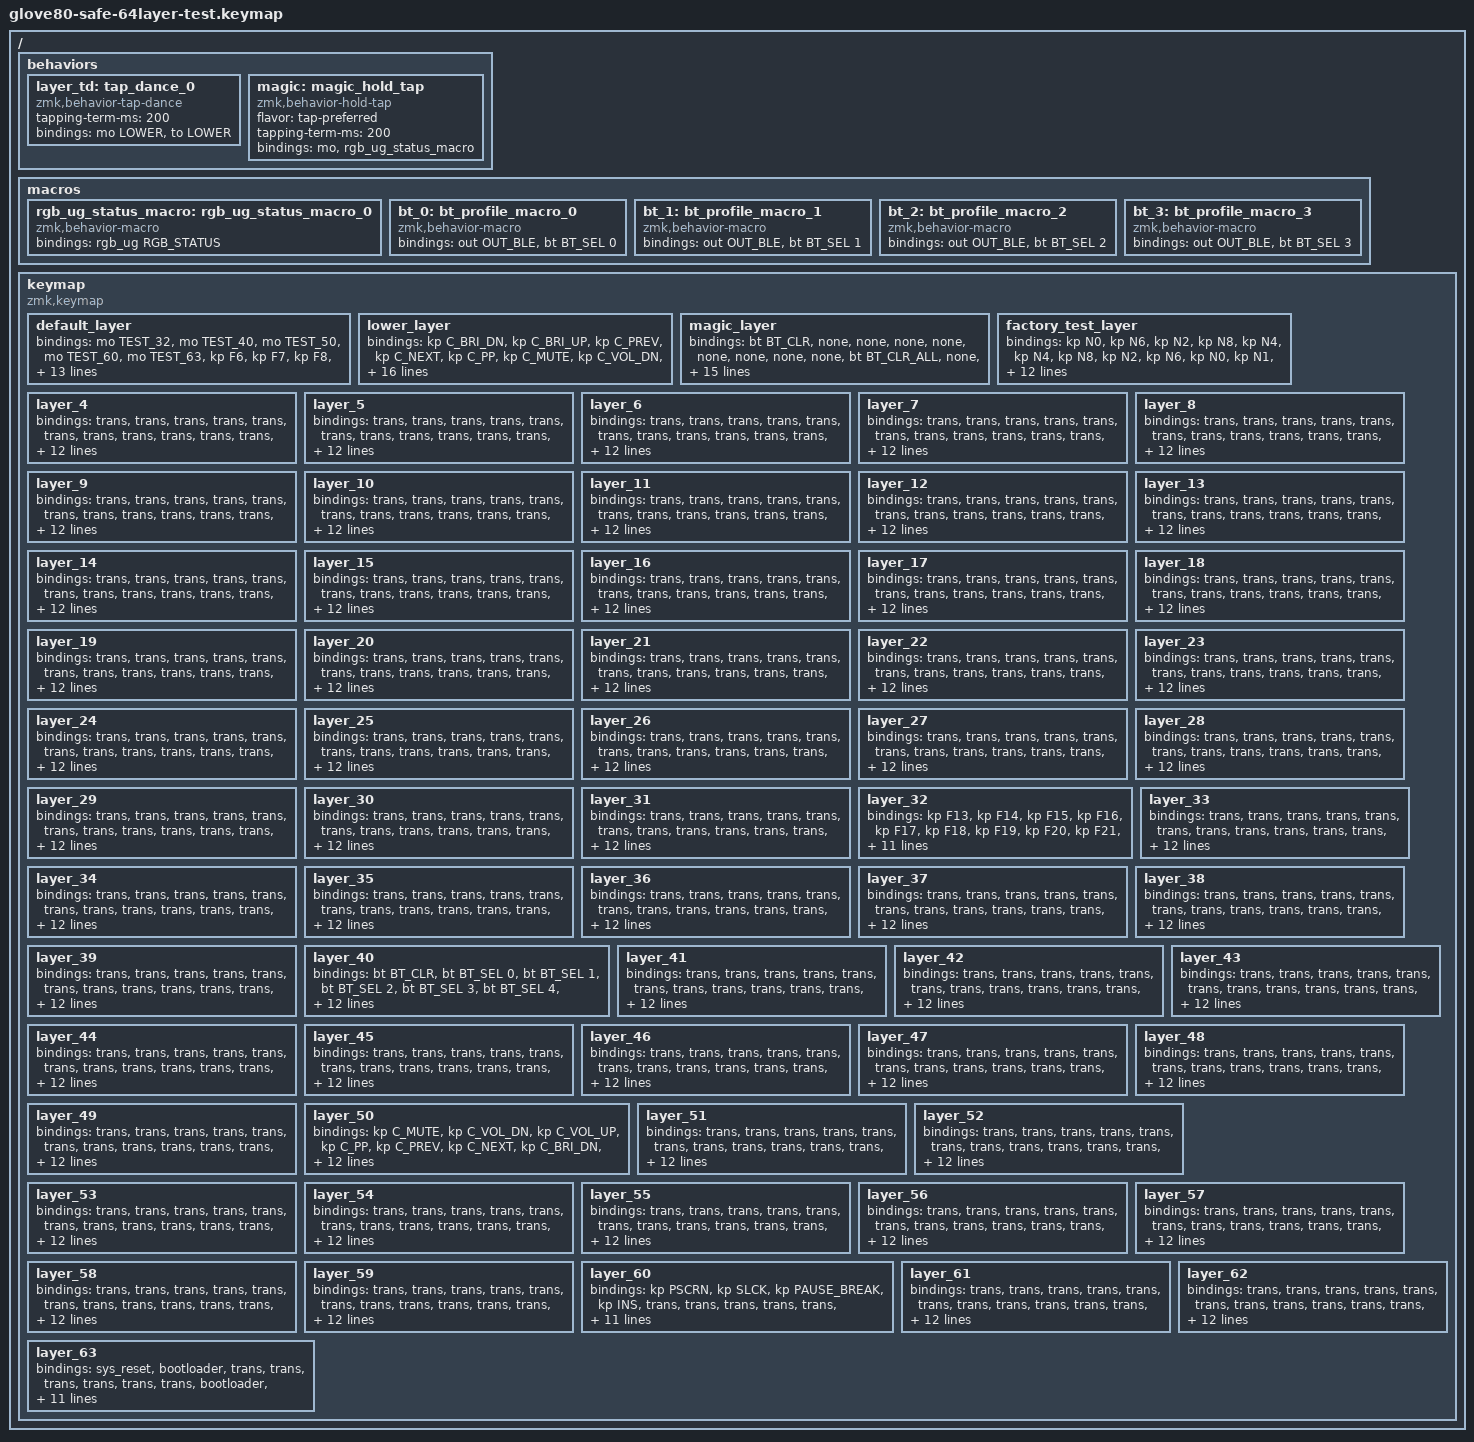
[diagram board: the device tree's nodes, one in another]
/*
 * SAFE 64-Layer Test Keymap for Glove80
 *
 * This keymap PRESERVES all MoErgo factory functionality:
 * - Layer 0 (DEFAULT): Standard Glove80 layout
 * - Layer 1 (LOWER): Function/numpad layer
 * - Layer 2 (MAGIC): Bootloader, reset, RGB, Bluetooth controls
 * - Layer 3 (FACTORY_TEST): Factory testing layer
 *
 * ADDS layers 4-63 to test 64-layer support:
 * - Layers 4-31: Empty placeholder layers (just &trans)
 * - Layers 32-63: Test layers with unique bindings to prove high layers work
 *
 * Test keys added to default layer (F1-F5 row):
 * - F1 = &mo 32 (access layer 32 - proves layers > 31 work!)
 * - F2 = &mo 40 (access layer 40)
 * - F3 = &mo 50 (access layer 50)
 * - F4 = &mo 60 (access layer 60)
 * - F5 = &mo 63 (access layer 63 - highest possible!)
 */

#include <behaviors.dtsi>
#include <dt-bindings/zmk/keys.h>
#include <dt-bindings/zmk/bt.h>
#include <dt-bindings/zmk/ext_power.h>
#include <dt-bindings/zmk/outputs.h>
#include <dt-bindings/zmk/rgb.h>

#define HYPER LC(LS(LG(LALT)))

// Factory layers (DO NOT CHANGE!)
#define DEFAULT 0
#define LOWER 1
#define MAGIC 2
#define FACTORY_TEST 3

// Test layers (layers 32+ ONLY work with 64-bit support!)
#define TEST_32 32
#define TEST_40 40
#define TEST_50 50
#define TEST_60 60
#define TEST_63 63

/ {
    behaviors {
        // Factory behaviors - DO NOT MODIFY
        layer_td: tap_dance_0 {
            compatible = "zmk,behavior-tap-dance";
            #binding-cells = <0>;
            tapping-term-ms = <200>;
            bindings = <&mo LOWER>, <&to LOWER>;
        };

        magic: magic_hold_tap {
            compatible = "zmk,behavior-hold-tap";
            #binding-cells = <2>;
            flavor = "tap-preferred";
            tapping-term-ms = <200>;
            bindings = <&mo>, <&rgb_ug_status_macro>;
        };
    };

    macros {
        // Factory macros - DO NOT MODIFY
        rgb_ug_status_macro: rgb_ug_status_macro_0 {
            compatible = "zmk,behavior-macro";
            #binding-cells = <0>;
            bindings = <&rgb_ug RGB_STATUS>;
        };

        bt_0: bt_profile_macro_0 {
            compatible = "zmk,behavior-macro";
            #binding-cells = <0>;
            bindings = <&out OUT_BLE>, <&bt BT_SEL 0>;
        };

        bt_1: bt_profile_macro_1 {
            compatible = "zmk,behavior-macro";
            #binding-cells = <0>;
            bindings = <&out OUT_BLE>, <&bt BT_SEL 1>;
        };

        bt_2: bt_profile_macro_2 {
            compatible = "zmk,behavior-macro";
            #binding-cells = <0>;
            bindings = <&out OUT_BLE>, <&bt BT_SEL 2>;
        };

        bt_3: bt_profile_macro_3 {
            compatible = "zmk,behavior-macro";
            #binding-cells = <0>;
            bindings = <&out OUT_BLE>, <&bt BT_SEL 3>;
        };
    };

    keymap {
        compatible = "zmk,keymap";

        // ====================================================================
        // LAYER 0: DEFAULT (Factory layout with test layer access on F-keys)
        // ====================================================================
        default_layer {
            // MODIFIED: F1-F5 now access test layers to prove 64-layer support works
            // Hold F1 = Layer 32, F2 = Layer 40, F3 = Layer 50, F4 = Layer 60, F5 = Layer 63
            // Release = return to base layer (momentary activation)

            bindings = <
            &mo TEST_32    &mo TEST_40 &mo TEST_50 &mo TEST_60 &mo TEST_63                                                                                        &kp F6  &kp F7      &kp F8      &kp F9      &kp F10
            &kp EQUAL      &kp N1      &kp N2      &kp N3      &kp N4      &kp N5                                                                     &kp N6  &kp N7  &kp N8      &kp N9      &kp N0      &kp MINUS
            &kp TAB        &kp Q       &kp W       &kp E       &kp R       &kp T                                                                      &kp Y   &kp U   &kp I       &kp O       &kp P       &kp BSLH
            &kp ESC        &kp A       &kp S       &kp D       &kp F       &kp G                                                                      &kp H   &kp J   &kp K       &kp L       &kp SEMI    &kp SQT
            &kp GRAVE      &kp Z       &kp X       &kp C       &kp V       &kp B   &kp LSHFT   &kp LCTRL   &layer_td  &kp LGUI  &kp RCTRL &kp RSHFT   &kp N   &kp M   &kp COMMA   &kp DOT     &kp FSLH    &kp PG_UP
            &magic MAGIC 0 &kp HOME    &kp END     &kp LEFT    &kp RIGHT           &kp BSPC    &kp DEL     &kp LALT   &kp RALT  &kp RET   &kp SPACE           &kp UP  &kp DOWN    &kp LBKT    &kp RBKT    &kp PG_DN
            >;
        };

        // ====================================================================
        // LAYER 1: LOWER (Factory - DO NOT MODIFY)
        // ====================================================================
        lower_layer {
            bindings = <
            &kp C_BRI_DN      &kp C_BRI_UP        &kp C_PREV      &kp C_NEXT      &kp C_PP                                                                                                           &kp C_MUTE   &kp C_VOL_DN &kp C_VOL_UP  &none           &kp PAUSE_BREAK
            &trans            &none               &none           &none           &none           &kp HOME                                                                              &kp LPAR     &kp KP_NUM   &kp KP_EQUAL &kp KP_DIVIDE &kp KP_MULTIPLY &kp PSCRN
            &trans            &none               &none           &kp UP          &none           &kp END                                                                               &kp RPAR     &kp KP_N7    &kp KP_N8    &kp KP_N9     &kp KP_MINUS    &kp SLCK
            &trans            &none               &kp LEFT        &kp DOWN        &kp RIGHT       &kp PG_UP                                                                             &kp PRCNT    &kp KP_N4    &kp KP_N5    &kp KP_N6     &kp KP_PLUS     &none
            &trans            &kp K_CMENU         &none           &kp F11         &kp F12         &kp PG_DN       &trans      &trans      &to DEFAULT &trans      &trans      &trans    &kp COMMA    &kp KP_N1    &kp KP_N2    &kp KP_N3     &kp KP_ENTER    &trans
            &trans            &kp CAPS            &kp INS         &kp F11         &kp F12                         &trans      &trans      &trans      &trans      &trans      &trans                 &kp KP_N0    &kp KP_N0    &kp KP_DOT    &kp KP_ENTER    &trans
            >;
        };

        // ====================================================================
        // LAYER 2: MAGIC (Factory - DO NOT MODIFY - CRITICAL FOR BOOTLOADER!)
        // ====================================================================
        magic_layer {
            bindings = <
            &bt BT_CLR        &none               &none           &none           &none                                                                                                           &none      &none      &none      &none      &bt BT_CLR_ALL
            &none             &none               &none           &none           &none           &none                                                                                &none      &none      &none      &none      &none      &none
            &none             &rgb_ug RGB_SPI     &rgb_ug RGB_SAI &rgb_ug RGB_HUI &rgb_ug RGB_BRI &rgb_ug RGB_TOG                                                                      &none      &none      &none      &none      &none      &none
            &bootloader       &rgb_ug RGB_SPD     &rgb_ug RGB_SAD &rgb_ug RGB_HUD &rgb_ug RGB_BRD &rgb_ug RGB_EFF                                                                      &none      &none      &none      &none      &none      &bootloader
            &sys_reset        &none               &none           &none           &none           &none           &bt_2     &bt_3     &none            &none     &none     &none       &none      &none      &none      &none      &none      &sys_reset
            &none             &none               &none           &none           &none                           &bt_0     &bt_1     &out OUT_USB     &none     &none     &none                  &none      &none      &none      &none      &to FACTORY_TEST
            >;
        };

        // ====================================================================
        // LAYER 3: FACTORY_TEST (Factory - DO NOT MODIFY)
        // ====================================================================
        factory_test_layer {
            bindings = <
            &kp N0   &kp N6   &kp N2   &kp N8   &kp N4                                                                              &kp N4   &kp N8   &kp N2   &kp N6   &kp N0
            &kp N1   &kp N7   &kp N3   &kp N9   &kp N5   &kp N0                                                            &kp N0   &kp N5   &kp N9   &kp N3   &kp N7   &kp N1
            &kp N2   &kp N8   &kp N4   &kp N0   &kp N6   &kp N1                                                            &kp N1   &kp N6   &kp N0   &kp N4   &kp N8   &kp N2
            &kp N3   &kp N9   &kp N5   &kp N1   &kp N7   &kp N2                                                            &kp N2   &kp N7   &kp N1   &kp N5   &kp N9   &kp N3
            &kp N4   &kp N0   &kp N6   &kp N2   &kp N8   &kp N3   &kp N4   &kp N5   &kp N6      &kp N6   &kp N5   &kp N4   &kp N3   &kp N8   &kp N2   &kp N6   &kp N0   &kp N4
            &kp N5   &kp N1   &kp N7   &kp N3   &kp N9            &kp N7   &kp N8   &kp N9      &kp N9   &kp N8   &kp N7            &kp N9   &kp N3   &kp N7   &kp N1   &kp N5
            >;
        };

        // ====================================================================
        // LAYERS 4-31: Placeholder layers (standard 32-bit support range)
        // ====================================================================
        // These layers just pass through to lower layers with &trans
        // They exist to fill the gap between factory layers and test layers

        layer_4  { bindings = <&trans &trans &trans &trans &trans &trans &trans &trans &trans &trans &trans &trans &trans &trans &trans &trans &trans &trans &trans &trans &trans &trans &trans &trans &trans &trans &trans &trans &trans &trans &trans &trans &trans &trans &trans &trans &trans &trans &trans &trans &trans &trans &trans &trans &trans &trans &trans &trans &trans &trans &trans &trans &trans &trans &trans &trans &trans &trans &trans &trans &trans &trans &trans &trans &trans &trans &trans &trans &trans &trans &trans &trans &trans &trans &trans &trans &trans &trans &trans &trans>; };
        layer_5  { bindings = <&trans &trans &trans &trans &trans &trans &trans &trans &trans &trans &trans &trans &trans &trans &trans &trans &trans &trans &trans &trans &trans &trans &trans &trans &trans &trans &trans &trans &trans &trans &trans &trans &trans &trans &trans &trans &trans &trans &trans &trans &trans &trans &trans &trans &trans &trans &trans &trans &trans &trans &trans &trans &trans &trans &trans &trans &trans &trans &trans &trans &trans &trans &trans &trans &trans &trans &trans &trans &trans &trans &trans &trans &trans &trans &trans &trans &trans &trans &trans &trans>; };
        layer_6  { bindings = <&trans &trans &trans &trans &trans &trans &trans &trans &trans &trans &trans &trans &trans &trans &trans &trans &trans &trans &trans &trans &trans &trans &trans &trans &trans &trans &trans &trans &trans &trans &trans &trans &trans &trans &trans &trans &trans &trans &trans &trans &trans &trans &trans &trans &trans &trans &trans &trans &trans &trans &trans &trans &trans &trans &trans &trans &trans &trans &trans &trans &trans &trans &trans &trans &trans &trans &trans &trans &trans &trans &trans &trans &trans &trans &trans &trans &trans &trans &trans &trans>; };
        layer_7  { bindings = <&trans &trans &trans &trans &trans &trans &trans &trans &trans &trans &trans &trans &trans &trans &trans &trans &trans &trans &trans &trans &trans &trans &trans &trans &trans &trans &trans &trans &trans &trans &trans &trans &trans &trans &trans &trans &trans &trans &trans &trans &trans &trans &trans &trans &trans &trans &trans &trans &trans &trans &trans &trans &trans &trans &trans &trans &trans &trans &trans &trans &trans &trans &trans &trans &trans &trans &trans &trans &trans &trans &trans &trans &trans &trans &trans &trans &trans &trans &trans &trans>; };
        layer_8  { bindings = <&trans &trans &trans &trans &trans &trans &trans &trans &trans &trans &trans &trans &trans &trans &trans &trans &trans &trans &trans &trans &trans &trans &trans &trans &trans &trans &trans &trans &trans &trans &trans &trans &trans &trans &trans &trans &trans &trans &trans &trans &trans &trans &trans &trans &trans &trans &trans &trans &trans &trans &trans &trans &trans &trans &trans &trans &trans &trans &trans &trans &trans &trans &trans &trans &trans &trans &trans &trans &trans &trans &trans &trans &trans &trans &trans &trans &trans &trans &trans &trans>; };
        layer_9  { bindings = <&trans &trans &trans &trans &trans &trans &trans &trans &trans &trans &trans &trans &trans &trans &trans &trans &trans &trans &trans &trans &trans &trans &trans &trans &trans &trans &trans &trans &trans &trans &trans &trans &trans &trans &trans &trans &trans &trans &trans &trans &trans &trans &trans &trans &trans &trans &trans &trans &trans &trans &trans &trans &trans &trans &trans &trans &trans &trans &trans &trans &trans &trans &trans &trans &trans &trans &trans &trans &trans &trans &trans &trans &trans &trans &trans &trans &trans &trans &trans &trans>; };
        layer_10 { bindings = <&trans &trans &trans &trans &trans &trans &trans &trans &trans &trans &trans &trans &trans &trans &trans &trans &trans &trans &trans &trans &trans &trans &trans &trans &trans &trans &trans &trans &trans &trans &trans &trans &trans &trans &trans &trans &trans &trans &trans &trans &trans &trans &trans &trans &trans &trans &trans &trans &trans &trans &trans &trans &trans &trans &trans &trans &trans &trans &trans &trans &trans &trans &trans &trans &trans &trans &trans &trans &trans &trans &trans &trans &trans &trans &trans &trans &trans &trans &trans &trans>; };
        layer_11 { bindings = <&trans &trans &trans &trans &trans &trans &trans &trans &trans &trans &trans &trans &trans &trans &trans &trans &trans &trans &trans &trans &trans &trans &trans &trans &trans &trans &trans &trans &trans &trans &trans &trans &trans &trans &trans &trans &trans &trans &trans &trans &trans &trans &trans &trans &trans &trans &trans &trans &trans &trans &trans &trans &trans &trans &trans &trans &trans &trans &trans &trans &trans &trans &trans &trans &trans &trans &trans &trans &trans &trans &trans &trans &trans &trans &trans &trans &trans &trans &trans &trans>; };
        layer_12 { bindings = <&trans &trans &trans &trans &trans &trans &trans &trans &trans &trans &trans &trans &trans &trans &trans &trans &trans &trans &trans &trans &trans &trans &trans &trans &trans &trans &trans &trans &trans &trans &trans &trans &trans &trans &trans &trans &trans &trans &trans &trans &trans &trans &trans &trans &trans &trans &trans &trans &trans &trans &trans &trans &trans &trans &trans &trans &trans &trans &trans &trans &trans &trans &trans &trans &trans &trans &trans &trans &trans &trans &trans &trans &trans &trans &trans &trans &trans &trans &trans &trans>; };
        layer_13 { bindings = <&trans &trans &trans &trans &trans &trans &trans &trans &trans &trans &trans &trans &trans &trans &trans &trans &trans &trans &trans &trans &trans &trans &trans &trans &trans &trans &trans &trans &trans &trans &trans &trans &trans &trans &trans &trans &trans &trans &trans &trans &trans &trans &trans &trans &trans &trans &trans &trans &trans &trans &trans &trans &trans &trans &trans &trans &trans &trans &trans &trans &trans &trans &trans &trans &trans &trans &trans &trans &trans &trans &trans &trans &trans &trans &trans &trans &trans &trans &trans &trans>; };
        layer_14 { bindings = <&trans &trans &trans &trans &trans &trans &trans &trans &trans &trans &trans &trans &trans &trans &trans &trans &trans &trans &trans &trans &trans &trans &trans &trans &trans &trans &trans &trans &trans &trans &trans &trans &trans &trans &trans &trans &trans &trans &trans &trans &trans &trans &trans &trans &trans &trans &trans &trans &trans &trans &trans &trans &trans &trans &trans &trans &trans &trans &trans &trans &trans &trans &trans &trans &trans &trans &trans &trans &trans &trans &trans &trans &trans &trans &trans &trans &trans &trans &trans &trans>; };
        layer_15 { bindings = <&trans &trans &trans &trans &trans &trans &trans &trans &trans &trans &trans &trans &trans &trans &trans &trans &trans &trans &trans &trans &trans &trans &trans &trans &trans &trans &trans &trans &trans &trans &trans &trans &trans &trans &trans &trans &trans &trans &trans &trans &trans &trans &trans &trans &trans &trans &trans &trans &trans &trans &trans &trans &trans &trans &trans &trans &trans &trans &trans &trans &trans &trans &trans &trans &trans &trans &trans &trans &trans &trans &trans &trans &trans &trans &trans &trans &trans &trans &trans &trans>; };
        layer_16 { bindings = <&trans &trans &trans &trans &trans &trans &trans &trans &trans &trans &trans &trans &trans &trans &trans &trans &trans &trans &trans &trans &trans &trans &trans &trans &trans &trans &trans &trans &trans &trans &trans &trans &trans &trans &trans &trans &trans &trans &trans &trans &trans &trans &trans &trans &trans &trans &trans &trans &trans &trans &trans &trans &trans &trans &trans &trans &trans &trans &trans &trans &trans &trans &trans &trans &trans &trans &trans &trans &trans &trans &trans &trans &trans &trans &trans &trans &trans &trans &trans &trans>; };
        layer_17 { bindings = <&trans &trans &trans &trans &trans &trans &trans &trans &trans &trans &trans &trans &trans &trans &trans &trans &trans &trans &trans &trans &trans &trans &trans &trans &trans &trans &trans &trans &trans &trans &trans &trans &trans &trans &trans &trans &trans &trans &trans &trans &trans &trans &trans &trans &trans &trans &trans &trans &trans &trans &trans &trans &trans &trans &trans &trans &trans &trans &trans &trans &trans &trans &trans &trans &trans &trans &trans &trans &trans &trans &trans &trans &trans &trans &trans &trans &trans &trans &trans &trans>; };
        layer_18 { bindings = <&trans &trans &trans &trans &trans &trans &trans &trans &trans &trans &trans &trans &trans &trans &trans &trans &trans &trans &trans &trans &trans &trans &trans &trans &trans &trans &trans &trans &trans &trans &trans &trans &trans &trans &trans &trans &trans &trans &trans &trans &trans &trans &trans &trans &trans &trans &trans &trans &trans &trans &trans &trans &trans &trans &trans &trans &trans &trans &trans &trans &trans &trans &trans &trans &trans &trans &trans &trans &trans &trans &trans &trans &trans &trans &trans &trans &trans &trans &trans &trans>; };
        layer_19 { bindings = <&trans &trans &trans &trans &trans &trans &trans &trans &trans &trans &trans &trans &trans &trans &trans &trans &trans &trans &trans &trans &trans &trans &trans &trans &trans &trans &trans &trans &trans &trans &trans &trans &trans &trans &trans &trans &trans &trans &trans &trans &trans &trans &trans &trans &trans &trans &trans &trans &trans &trans &trans &trans &trans &trans &trans &trans &trans &trans &trans &trans &trans &trans &trans &trans &trans &trans &trans &trans &trans &trans &trans &trans &trans &trans &trans &trans &trans &trans &trans &trans>; };
        layer_20 { bindings = <&trans &trans &trans &trans &trans &trans &trans &trans &trans &trans &trans &trans &trans &trans &trans &trans &trans &trans &trans &trans &trans &trans &trans &trans &trans &trans &trans &trans &trans &trans &trans &trans &trans &trans &trans &trans &trans &trans &trans &trans &trans &trans &trans &trans &trans &trans &trans &trans &trans &trans &trans &trans &trans &trans &trans &trans &trans &trans &trans &trans &trans &trans &trans &trans &trans &trans &trans &trans &trans &trans &trans &trans &trans &trans &trans &trans &trans &trans &trans &trans>; };
        layer_21 { bindings = <&trans &trans &trans &trans &trans &trans &trans &trans &trans &trans &trans &trans &trans &trans &trans &trans &trans &trans &trans &trans &trans &trans &trans &trans &trans &trans &trans &trans &trans &trans &trans &trans &trans &trans &trans &trans &trans &trans &trans &trans &trans &trans &trans &trans &trans &trans &trans &trans &trans &trans &trans &trans &trans &trans &trans &trans &trans &trans &trans &trans &trans &trans &trans &trans &trans &trans &trans &trans &trans &trans &trans &trans &trans &trans &trans &trans &trans &trans &trans &trans>; };
        layer_22 { bindings = <&trans &trans &trans &trans &trans &trans &trans &trans &trans &trans &trans &trans &trans &trans &trans &trans &trans &trans &trans &trans &trans &trans &trans &trans &trans &trans &trans &trans &trans &trans &trans &trans &trans &trans &trans &trans &trans &trans &trans &trans &trans &trans &trans &trans &trans &trans &trans &trans &trans &trans &trans &trans &trans &trans &trans &trans &trans &trans &trans &trans &trans &trans &trans &trans &trans &trans &trans &trans &trans &trans &trans &trans &trans &trans &trans &trans &trans &trans &trans &trans>; };
        layer_23 { bindings = <&trans &trans &trans &trans &trans &trans &trans &trans &trans &trans &trans &trans &trans &trans &trans &trans &trans &trans &trans &trans &trans &trans &trans &trans &trans &trans &trans &trans &trans &trans &trans &trans &trans &trans &trans &trans &trans &trans &trans &trans &trans &trans &trans &trans &trans &trans &trans &trans &trans &trans &trans &trans &trans &trans &trans &trans &trans &trans &trans &trans &trans &trans &trans &trans &trans &trans &trans &trans &trans &trans &trans &trans &trans &trans &trans &trans &trans &trans &trans &trans>; };
        layer_24 { bindings = <&trans &trans &trans &trans &trans &trans &trans &trans &trans &trans &trans &trans &trans &trans &trans &trans &trans &trans &trans &trans &trans &trans &trans &trans &trans &trans &trans &trans &trans &trans &trans &trans &trans &trans &trans &trans &trans &trans &trans &trans &trans &trans &trans &trans &trans &trans &trans &trans &trans &trans &trans &trans &trans &trans &trans &trans &trans &trans &trans &trans &trans &trans &trans &trans &trans &trans &trans &trans &trans &trans &trans &trans &trans &trans &trans &trans &trans &trans &trans &trans>; };
        layer_25 { bindings = <&trans &trans &trans &trans &trans &trans &trans &trans &trans &trans &trans &trans &trans &trans &trans &trans &trans &trans &trans &trans &trans &trans &trans &trans &trans &trans &trans &trans &trans &trans &trans &trans &trans &trans &trans &trans &trans &trans &trans &trans &trans &trans &trans &trans &trans &trans &trans &trans &trans &trans &trans &trans &trans &trans &trans &trans &trans &trans &trans &trans &trans &trans &trans &trans &trans &trans &trans &trans &trans &trans &trans &trans &trans &trans &trans &trans &trans &trans &trans &trans>; };
        layer_26 { bindings = <&trans &trans &trans &trans &trans &trans &trans &trans &trans &trans &trans &trans &trans &trans &trans &trans &trans &trans &trans &trans &trans &trans &trans &trans &trans &trans &trans &trans &trans &trans &trans &trans &trans &trans &trans &trans &trans &trans &trans &trans &trans &trans &trans &trans &trans &trans &trans &trans &trans &trans &trans &trans &trans &trans &trans &trans &trans &trans &trans &trans &trans &trans &trans &trans &trans &trans &trans &trans &trans &trans &trans &trans &trans &trans &trans &trans &trans &trans &trans &trans>; };
        layer_27 { bindings = <&trans &trans &trans &trans &trans &trans &trans &trans &trans &trans &trans &trans &trans &trans &trans &trans &trans &trans &trans &trans &trans &trans &trans &trans &trans &trans &trans &trans &trans &trans &trans &trans &trans &trans &trans &trans &trans &trans &trans &trans &trans &trans &trans &trans &trans &trans &trans &trans &trans &trans &trans &trans &trans &trans &trans &trans &trans &trans &trans &trans &trans &trans &trans &trans &trans &trans &trans &trans &trans &trans &trans &trans &trans &trans &trans &trans &trans &trans &trans &trans>; };
        layer_28 { bindings = <&trans &trans &trans &trans &trans &trans &trans &trans &trans &trans &trans &trans &trans &trans &trans &trans &trans &trans &trans &trans &trans &trans &trans &trans &trans &trans &trans &trans &trans &trans &trans &trans &trans &trans &trans &trans &trans &trans &trans &trans &trans &trans &trans &trans &trans &trans &trans &trans &trans &trans &trans &trans &trans &trans &trans &trans &trans &trans &trans &trans &trans &trans &trans &trans &trans &trans &trans &trans &trans &trans &trans &trans &trans &trans &trans &trans &trans &trans &trans &trans>; };
        layer_29 { bindings = <&trans &trans &trans &trans &trans &trans &trans &trans &trans &trans &trans &trans &trans &trans &trans &trans &trans &trans &trans &trans &trans &trans &trans &trans &trans &trans &trans &trans &trans &trans &trans &trans &trans &trans &trans &trans &trans &trans &trans &trans &trans &trans &trans &trans &trans &trans &trans &trans &trans &trans &trans &trans &trans &trans &trans &trans &trans &trans &trans &trans &trans &trans &trans &trans &trans &trans &trans &trans &trans &trans &trans &trans &trans &trans &trans &trans &trans &trans &trans &trans>; };
        layer_30 { bindings = <&trans &trans &trans &trans &trans &trans &trans &trans &trans &trans &trans &trans &trans &trans &trans &trans &trans &trans &trans &trans &trans &trans &trans &trans &trans &trans &trans &trans &trans &trans &trans &trans &trans &trans &trans &trans &trans &trans &trans &trans &trans &trans &trans &trans &trans &trans &trans &trans &trans &trans &trans &trans &trans &trans &trans &trans &trans &trans &trans &trans &trans &trans &trans &trans &trans &trans &trans &trans &trans &trans &trans &trans &trans &trans &trans &trans &trans &trans &trans &trans>; };
        layer_31 { bindings = <&trans &trans &trans &trans &trans &trans &trans &trans &trans &trans &trans &trans &trans &trans &trans &trans &trans &trans &trans &trans &trans &trans &trans &trans &trans &trans &trans &trans &trans &trans &trans &trans &trans &trans &trans &trans &trans &trans &trans &trans &trans &trans &trans &trans &trans &trans &trans &trans &trans &trans &trans &trans &trans &trans &trans &trans &trans &trans &trans &trans &trans &trans &trans &trans &trans &trans &trans &trans &trans &trans &trans &trans &trans &trans &trans &trans &trans &trans &trans &trans>; };

        // ====================================================================
        // *** LAYERS 32-63: HIGH LAYERS - ONLY WORK WITH 64-BIT SUPPORT! ***
        // ====================================================================
        // If these layers work, it PROVES the 64-layer patch is functioning!

        // LAYER 32: Test layer with X, Y, Z letters (accessed by holding F1 key)
        // Type to see X's, Y's, Z's - proves layer 32 is active!
        layer_32 {
            bindings = <
            &kp F13  &kp F14  &kp F15  &kp F16  &kp F17                                                                                                 &kp F18  &kp F19  &kp F20  &kp F21  &kp F22
            &kp F23  &kp F24  &kp X    &kp X    &kp X    &kp X                                                                               &kp Y    &kp Y    &kp Y    &kp Y    &kp Y    &kp Y
            &trans   &kp X    &kp X    &kp X    &kp X    &kp X                                                                               &kp Y    &kp Y    &kp Y    &kp Y    &kp Y    &trans
            &trans   &kp Z    &kp Z    &kp Z    &kp Z    &kp Z                                                                               &kp Y    &kp Y    &kp Y    &kp Y    &kp Y    &trans
            &trans   &kp Z    &kp Z    &kp Z    &kp Z    &kp Z    &trans   &trans   &trans      &trans   &trans   &trans                    &kp Y    &kp Y    &kp Y    &kp Y    &kp Y    &trans
            &trans   &trans   &trans   &trans   &trans            &trans   &trans   &trans      &trans   &trans   &trans                             &trans   &trans   &trans   &trans   &trans
            >;
        };

        // Layers 33-39: Placeholder
        layer_33 { bindings = <&trans &trans &trans &trans &trans &trans &trans &trans &trans &trans &trans &trans &trans &trans &trans &trans &trans &trans &trans &trans &trans &trans &trans &trans &trans &trans &trans &trans &trans &trans &trans &trans &trans &trans &trans &trans &trans &trans &trans &trans &trans &trans &trans &trans &trans &trans &trans &trans &trans &trans &trans &trans &trans &trans &trans &trans &trans &trans &trans &trans &trans &trans &trans &trans &trans &trans &trans &trans &trans &trans &trans &trans &trans &trans &trans &trans &trans &trans &trans &trans>; };
        layer_34 { bindings = <&trans &trans &trans &trans &trans &trans &trans &trans &trans &trans &trans &trans &trans &trans &trans &trans &trans &trans &trans &trans &trans &trans &trans &trans &trans &trans &trans &trans &trans &trans &trans &trans &trans &trans &trans &trans &trans &trans &trans &trans &trans &trans &trans &trans &trans &trans &trans &trans &trans &trans &trans &trans &trans &trans &trans &trans &trans &trans &trans &trans &trans &trans &trans &trans &trans &trans &trans &trans &trans &trans &trans &trans &trans &trans &trans &trans &trans &trans &trans &trans>; };
        layer_35 { bindings = <&trans &trans &trans &trans &trans &trans &trans &trans &trans &trans &trans &trans &trans &trans &trans &trans &trans &trans &trans &trans &trans &trans &trans &trans &trans &trans &trans &trans &trans &trans &trans &trans &trans &trans &trans &trans &trans &trans &trans &trans &trans &trans &trans &trans &trans &trans &trans &trans &trans &trans &trans &trans &trans &trans &trans &trans &trans &trans &trans &trans &trans &trans &trans &trans &trans &trans &trans &trans &trans &trans &trans &trans &trans &trans &trans &trans &trans &trans &trans &trans>; };
        layer_36 { bindings = <&trans &trans &trans &trans &trans &trans &trans &trans &trans &trans &trans &trans &trans &trans &trans &trans &trans &trans &trans &trans &trans &trans &trans &trans &trans &trans &trans &trans &trans &trans &trans &trans &trans &trans &trans &trans &trans &trans &trans &trans &trans &trans &trans &trans &trans &trans &trans &trans &trans &trans &trans &trans &trans &trans &trans &trans &trans &trans &trans &trans &trans &trans &trans &trans &trans &trans &trans &trans &trans &trans &trans &trans &trans &trans &trans &trans &trans &trans &trans &trans>; };
        layer_37 { bindings = <&trans &trans &trans &trans &trans &trans &trans &trans &trans &trans &trans &trans &trans &trans &trans &trans &trans &trans &trans &trans &trans &trans &trans &trans &trans &trans &trans &trans &trans &trans &trans &trans &trans &trans &trans &trans &trans &trans &trans &trans &trans &trans &trans &trans &trans &trans &trans &trans &trans &trans &trans &trans &trans &trans &trans &trans &trans &trans &trans &trans &trans &trans &trans &trans &trans &trans &trans &trans &trans &trans &trans &trans &trans &trans &trans &trans &trans &trans &trans &trans>; };
        layer_38 { bindings = <&trans &trans &trans &trans &trans &trans &trans &trans &trans &trans &trans &trans &trans &trans &trans &trans &trans &trans &trans &trans &trans &trans &trans &trans &trans &trans &trans &trans &trans &trans &trans &trans &trans &trans &trans &trans &trans &trans &trans &trans &trans &trans &trans &trans &trans &trans &trans &trans &trans &trans &trans &trans &trans &trans &trans &trans &trans &trans &trans &trans &trans &trans &trans &trans &trans &trans &trans &trans &trans &trans &trans &trans &trans &trans &trans &trans &trans &trans &trans &trans>; };
        layer_39 { bindings = <&trans &trans &trans &trans &trans &trans &trans &trans &trans &trans &trans &trans &trans &trans &trans &trans &trans &trans &trans &trans &trans &trans &trans &trans &trans &trans &trans &trans &trans &trans &trans &trans &trans &trans &trans &trans &trans &trans &trans &trans &trans &trans &trans &trans &trans &trans &trans &trans &trans &trans &trans &trans &trans &trans &trans &trans &trans &trans &trans &trans &trans &trans &trans &trans &trans &trans &trans &trans &trans &trans &trans &trans &trans &trans &trans &trans &trans &trans &trans &trans>; };

        // LAYER 40: Test layer with A, B, C letters + Bluetooth (accessed by holding F2 key)
        // Type to see A's, B's, C's - proves layer 40 is active!
        layer_40 {
            bindings = <
            &bt BT_CLR  &bt BT_SEL 0  &bt BT_SEL 1  &bt BT_SEL 2  &bt BT_SEL 3                                                                     &bt BT_SEL 4  &out OUT_BLE  &out OUT_USB  &trans  &trans
            &trans      &kp A         &kp A         &kp A         &kp A         &kp A                                                     &kp B    &kp B         &kp B         &kp B         &kp B   &trans
            &trans      &kp A         &kp A         &kp A         &kp A         &kp A                                                     &kp B    &kp B         &kp B         &kp B         &kp B   &trans
            &trans      &kp C         &kp C         &kp C         &kp C         &kp C                                                     &kp B    &kp B         &kp B         &kp B         &kp B   &trans
            &trans      &kp C         &kp C         &kp C         &kp C         &kp C   &trans  &trans  &trans    &trans  &trans  &trans  &kp B    &kp B         &kp B         &kp B         &kp B   &trans
            &trans      &trans        &trans        &trans        &trans                &trans  &trans  &trans    &trans  &trans  &trans           &trans        &trans        &trans        &trans  &trans
            >;
        };

        // Layers 41-49: Placeholder
        layer_41 { bindings = <&trans &trans &trans &trans &trans &trans &trans &trans &trans &trans &trans &trans &trans &trans &trans &trans &trans &trans &trans &trans &trans &trans &trans &trans &trans &trans &trans &trans &trans &trans &trans &trans &trans &trans &trans &trans &trans &trans &trans &trans &trans &trans &trans &trans &trans &trans &trans &trans &trans &trans &trans &trans &trans &trans &trans &trans &trans &trans &trans &trans &trans &trans &trans &trans &trans &trans &trans &trans &trans &trans &trans &trans &trans &trans &trans &trans &trans &trans &trans &trans>; };
        layer_42 { bindings = <&trans &trans &trans &trans &trans &trans &trans &trans &trans &trans &trans &trans &trans &trans &trans &trans &trans &trans &trans &trans &trans &trans &trans &trans &trans &trans &trans &trans &trans &trans &trans &trans &trans &trans &trans &trans &trans &trans &trans &trans &trans &trans &trans &trans &trans &trans &trans &trans &trans &trans &trans &trans &trans &trans &trans &trans &trans &trans &trans &trans &trans &trans &trans &trans &trans &trans &trans &trans &trans &trans &trans &trans &trans &trans &trans &trans &trans &trans &trans &trans>; };
        layer_43 { bindings = <&trans &trans &trans &trans &trans &trans &trans &trans &trans &trans &trans &trans &trans &trans &trans &trans &trans &trans &trans &trans &trans &trans &trans &trans &trans &trans &trans &trans &trans &trans &trans &trans &trans &trans &trans &trans &trans &trans &trans &trans &trans &trans &trans &trans &trans &trans &trans &trans &trans &trans &trans &trans &trans &trans &trans &trans &trans &trans &trans &trans &trans &trans &trans &trans &trans &trans &trans &trans &trans &trans &trans &trans &trans &trans &trans &trans &trans &trans &trans &trans>; };
        layer_44 { bindings = <&trans &trans &trans &trans &trans &trans &trans &trans &trans &trans &trans &trans &trans &trans &trans &trans &trans &trans &trans &trans &trans &trans &trans &trans &trans &trans &trans &trans &trans &trans &trans &trans &trans &trans &trans &trans &trans &trans &trans &trans &trans &trans &trans &trans &trans &trans &trans &trans &trans &trans &trans &trans &trans &trans &trans &trans &trans &trans &trans &trans &trans &trans &trans &trans &trans &trans &trans &trans &trans &trans &trans &trans &trans &trans &trans &trans &trans &trans &trans &trans>; };
        layer_45 { bindings = <&trans &trans &trans &trans &trans &trans &trans &trans &trans &trans &trans &trans &trans &trans &trans &trans &trans &trans &trans &trans &trans &trans &trans &trans &trans &trans &trans &trans &trans &trans &trans &trans &trans &trans &trans &trans &trans &trans &trans &trans &trans &trans &trans &trans &trans &trans &trans &trans &trans &trans &trans &trans &trans &trans &trans &trans &trans &trans &trans &trans &trans &trans &trans &trans &trans &trans &trans &trans &trans &trans &trans &trans &trans &trans &trans &trans &trans &trans &trans &trans>; };
        layer_46 { bindings = <&trans &trans &trans &trans &trans &trans &trans &trans &trans &trans &trans &trans &trans &trans &trans &trans &trans &trans &trans &trans &trans &trans &trans &trans &trans &trans &trans &trans &trans &trans &trans &trans &trans &trans &trans &trans &trans &trans &trans &trans &trans &trans &trans &trans &trans &trans &trans &trans &trans &trans &trans &trans &trans &trans &trans &trans &trans &trans &trans &trans &trans &trans &trans &trans &trans &trans &trans &trans &trans &trans &trans &trans &trans &trans &trans &trans &trans &trans &trans &trans>; };
        layer_47 { bindings = <&trans &trans &trans &trans &trans &trans &trans &trans &trans &trans &trans &trans &trans &trans &trans &trans &trans &trans &trans &trans &trans &trans &trans &trans &trans &trans &trans &trans &trans &trans &trans &trans &trans &trans &trans &trans &trans &trans &trans &trans &trans &trans &trans &trans &trans &trans &trans &trans &trans &trans &trans &trans &trans &trans &trans &trans &trans &trans &trans &trans &trans &trans &trans &trans &trans &trans &trans &trans &trans &trans &trans &trans &trans &trans &trans &trans &trans &trans &trans &trans>; };
        layer_48 { bindings = <&trans &trans &trans &trans &trans &trans &trans &trans &trans &trans &trans &trans &trans &trans &trans &trans &trans &trans &trans &trans &trans &trans &trans &trans &trans &trans &trans &trans &trans &trans &trans &trans &trans &trans &trans &trans &trans &trans &trans &trans &trans &trans &trans &trans &trans &trans &trans &trans &trans &trans &trans &trans &trans &trans &trans &trans &trans &trans &trans &trans &trans &trans &trans &trans &trans &trans &trans &trans &trans &trans &trans &trans &trans &trans &trans &trans &trans &trans &trans &trans>; };
        layer_49 { bindings = <&trans &trans &trans &trans &trans &trans &trans &trans &trans &trans &trans &trans &trans &trans &trans &trans &trans &trans &trans &trans &trans &trans &trans &trans &trans &trans &trans &trans &trans &trans &trans &trans &trans &trans &trans &trans &trans &trans &trans &trans &trans &trans &trans &trans &trans &trans &trans &trans &trans &trans &trans &trans &trans &trans &trans &trans &trans &trans &trans &trans &trans &trans &trans &trans &trans &trans &trans &trans &trans &trans &trans &trans &trans &trans &trans &trans &trans &trans &trans &trans>; };

        // LAYER 50: Test layer with D, E, F letters + Media (accessed by holding F3 key)
        // Type to see D's, E's, F's - proves layer 50 is active!
        layer_50 {
            bindings = <
            &kp C_MUTE  &kp C_VOL_DN  &kp C_VOL_UP  &kp C_PP  &kp C_PREV                                                                             &kp C_NEXT  &kp C_BRI_DN  &kp C_BRI_UP  &trans  &trans
            &trans      &kp D         &kp D         &kp D     &kp D       &kp D                                                             &kp E    &kp E         &kp E         &kp E         &kp E   &trans
            &trans      &kp D         &kp D         &kp D     &kp D       &kp D                                                             &kp E    &kp E         &kp E         &kp E         &kp E   &trans
            &trans      &kp F         &kp F         &kp F     &kp F       &kp F                                                             &kp E    &kp E         &kp E         &kp E         &kp E   &trans
            &trans      &kp F         &kp F         &kp F     &kp F       &kp F   &trans  &trans  &trans    &trans  &trans  &trans         &kp E    &kp E         &kp E         &kp E         &kp E   &trans
            &trans      &trans        &trans        &trans    &trans              &trans  &trans  &trans    &trans  &trans  &trans                  &trans        &trans        &trans        &trans  &trans
            >;
        };

        // Layers 51-59: Placeholder
        layer_51 { bindings = <&trans &trans &trans &trans &trans &trans &trans &trans &trans &trans &trans &trans &trans &trans &trans &trans &trans &trans &trans &trans &trans &trans &trans &trans &trans &trans &trans &trans &trans &trans &trans &trans &trans &trans &trans &trans &trans &trans &trans &trans &trans &trans &trans &trans &trans &trans &trans &trans &trans &trans &trans &trans &trans &trans &trans &trans &trans &trans &trans &trans &trans &trans &trans &trans &trans &trans &trans &trans &trans &trans &trans &trans &trans &trans &trans &trans &trans &trans &trans &trans>; };
        layer_52 { bindings = <&trans &trans &trans &trans &trans &trans &trans &trans &trans &trans &trans &trans &trans &trans &trans &trans &trans &trans &trans &trans &trans &trans &trans &trans &trans &trans &trans &trans &trans &trans &trans &trans &trans &trans &trans &trans &trans &trans &trans &trans &trans &trans &trans &trans &trans &trans &trans &trans &trans &trans &trans &trans &trans &trans &trans &trans &trans &trans &trans &trans &trans &trans &trans &trans &trans &trans &trans &trans &trans &trans &trans &trans &trans &trans &trans &trans &trans &trans &trans &trans>; };
        layer_53 { bindings = <&trans &trans &trans &trans &trans &trans &trans &trans &trans &trans &trans &trans &trans &trans &trans &trans &trans &trans &trans &trans &trans &trans &trans &trans &trans &trans &trans &trans &trans &trans &trans &trans &trans &trans &trans &trans &trans &trans &trans &trans &trans &trans &trans &trans &trans &trans &trans &trans &trans &trans &trans &trans &trans &trans &trans &trans &trans &trans &trans &trans &trans &trans &trans &trans &trans &trans &trans &trans &trans &trans &trans &trans &trans &trans &trans &trans &trans &trans &trans &trans>; };
        layer_54 { bindings = <&trans &trans &trans &trans &trans &trans &trans &trans &trans &trans &trans &trans &trans &trans &trans &trans &trans &trans &trans &trans &trans &trans &trans &trans &trans &trans &trans &trans &trans &trans &trans &trans &trans &trans &trans &trans &trans &trans &trans &trans &trans &trans &trans &trans &trans &trans &trans &trans &trans &trans &trans &trans &trans &trans &trans &trans &trans &trans &trans &trans &trans &trans &trans &trans &trans &trans &trans &trans &trans &trans &trans &trans &trans &trans &trans &trans &trans &trans &trans &trans>; };
        layer_55 { bindings = <&trans &trans &trans &trans &trans &trans &trans &trans &trans &trans &trans &trans &trans &trans &trans &trans &trans &trans &trans &trans &trans &trans &trans &trans &trans &trans &trans &trans &trans &trans &trans &trans &trans &trans &trans &trans &trans &trans &trans &trans &trans &trans &trans &trans &trans &trans &trans &trans &trans &trans &trans &trans &trans &trans &trans &trans &trans &trans &trans &trans &trans &trans &trans &trans &trans &trans &trans &trans &trans &trans &trans &trans &trans &trans &trans &trans &trans &trans &trans &trans>; };
        layer_56 { bindings = <&trans &trans &trans &trans &trans &trans &trans &trans &trans &trans &trans &trans &trans &trans &trans &trans &trans &trans &trans &trans &trans &trans &trans &trans &trans &trans &trans &trans &trans &trans &trans &trans &trans &trans &trans &trans &trans &trans &trans &trans &trans &trans &trans &trans &trans &trans &trans &trans &trans &trans &trans &trans &trans &trans &trans &trans &trans &trans &trans &trans &trans &trans &trans &trans &trans &trans &trans &trans &trans &trans &trans &trans &trans &trans &trans &trans &trans &trans &trans &trans>; };
        layer_57 { bindings = <&trans &trans &trans &trans &trans &trans &trans &trans &trans &trans &trans &trans &trans &trans &trans &trans &trans &trans &trans &trans &trans &trans &trans &trans &trans &trans &trans &trans &trans &trans &trans &trans &trans &trans &trans &trans &trans &trans &trans &trans &trans &trans &trans &trans &trans &trans &trans &trans &trans &trans &trans &trans &trans &trans &trans &trans &trans &trans &trans &trans &trans &trans &trans &trans &trans &trans &trans &trans &trans &trans &trans &trans &trans &trans &trans &trans &trans &trans &trans &trans>; };
        layer_58 { bindings = <&trans &trans &trans &trans &trans &trans &trans &trans &trans &trans &trans &trans &trans &trans &trans &trans &trans &trans &trans &trans &trans &trans &trans &trans &trans &trans &trans &trans &trans &trans &trans &trans &trans &trans &trans &trans &trans &trans &trans &trans &trans &trans &trans &trans &trans &trans &trans &trans &trans &trans &trans &trans &trans &trans &trans &trans &trans &trans &trans &trans &trans &trans &trans &trans &trans &trans &trans &trans &trans &trans &trans &trans &trans &trans &trans &trans &trans &trans &trans &trans>; };
        layer_59 { bindings = <&trans &trans &trans &trans &trans &trans &trans &trans &trans &trans &trans &trans &trans &trans &trans &trans &trans &trans &trans &trans &trans &trans &trans &trans &trans &trans &trans &trans &trans &trans &trans &trans &trans &trans &trans &trans &trans &trans &trans &trans &trans &trans &trans &trans &trans &trans &trans &trans &trans &trans &trans &trans &trans &trans &trans &trans &trans &trans &trans &trans &trans &trans &trans &trans &trans &trans &trans &trans &trans &trans &trans &trans &trans &trans &trans &trans &trans &trans &trans &trans>; };

        // LAYER 60: Test layer with G, H, I letters + System keys (accessed by holding F4 key)
        // Type to see G's, H's, I's - proves layer 60 is active!
        layer_60 {
            bindings = <
            &kp PSCRN  &kp SLCK  &kp PAUSE_BREAK  &kp INS  &trans                                                                                   &trans  &trans  &trans  &trans  &trans
            &trans     &kp G     &kp G            &kp G    &kp G    &kp G                                                                  &kp H    &kp H   &kp H   &kp H   &kp H   &trans
            &trans     &kp G     &kp G            &kp G    &kp G    &kp G                                                                  &kp H    &kp H   &kp H   &kp H   &kp H   &trans
            &trans     &kp I     &kp I            &kp I    &kp I    &kp I                                                                  &kp H    &kp H   &kp H   &kp H   &kp H   &trans
            &trans     &kp I     &kp I            &kp I    &kp I    &kp I   &trans  &trans  &trans    &trans  &trans  &trans              &kp H    &kp H   &kp H   &kp H   &kp H   &trans
            &trans     &trans    &trans           &trans   &trans           &trans  &trans  &trans    &trans  &trans  &trans                       &trans  &trans  &trans  &trans  &trans
            >;
        };

        // Layers 61-62: Placeholder
        layer_61 { bindings = <&trans &trans &trans &trans &trans &trans &trans &trans &trans &trans &trans &trans &trans &trans &trans &trans &trans &trans &trans &trans &trans &trans &trans &trans &trans &trans &trans &trans &trans &trans &trans &trans &trans &trans &trans &trans &trans &trans &trans &trans &trans &trans &trans &trans &trans &trans &trans &trans &trans &trans &trans &trans &trans &trans &trans &trans &trans &trans &trans &trans &trans &trans &trans &trans &trans &trans &trans &trans &trans &trans &trans &trans &trans &trans &trans &trans &trans &trans &trans &trans>; };
        layer_62 { bindings = <&trans &trans &trans &trans &trans &trans &trans &trans &trans &trans &trans &trans &trans &trans &trans &trans &trans &trans &trans &trans &trans &trans &trans &trans &trans &trans &trans &trans &trans &trans &trans &trans &trans &trans &trans &trans &trans &trans &trans &trans &trans &trans &trans &trans &trans &trans &trans &trans &trans &trans &trans &trans &trans &trans &trans &trans &trans &trans &trans &trans &trans &trans &trans &trans &trans &trans &trans &trans &trans &trans &trans &trans &trans &trans &trans &trans &trans &trans &trans &trans>; };

        // LAYER 63: HIGHEST LAYER POSSIBLE! (accessed by holding F5 key)
        // Type to see J's, K's, L's - proves layer 63 (the highest!) is active!
        layer_63 {
            bindings = <
            &sys_reset  &bootloader  &trans  &trans  &trans                                                                                        &trans  &trans  &trans  &bootloader  &sys_reset
            &trans      &kp J        &kp J   &kp J   &kp J   &kp J                                                                        &kp K    &kp K   &kp K   &kp K   &kp K        &trans
            &trans      &kp J        &kp J   &kp J   &kp J   &kp J                                                                        &kp K    &kp K   &kp K   &kp K   &kp K        &trans
            &trans      &kp L        &kp L   &kp L   &kp L   &kp L                                                                        &kp K    &kp K   &kp K   &kp K   &kp K        &trans
            &trans      &kp L        &kp L   &kp L   &kp L   &kp L   &trans  &trans  &trans    &trans  &trans  &trans                    &kp K    &kp K   &kp K   &kp K   &kp K        &trans
            &trans      &trans       &trans  &trans  &trans          &trans  &trans  &trans    &trans  &trans  &trans                             &trans  &trans  &trans  &trans       &trans
            >;
        };
    };
};
